AUTOSAR XML (schema 00046)
package /Cluster
  flexray cluster Chassis: baudrate=10000000, action-point-offset=2, cycle=0.005, macro-per-cycle=5000, macrotick-duration=1E-6, minislot-duration=5, network-idle-time=40, number-of-minislots=492, number-of-static-slots=50, payload-length-static=4, static-slot-duration=50
    flexray physical channel ChassisA: channel-name=CHANNEL-A
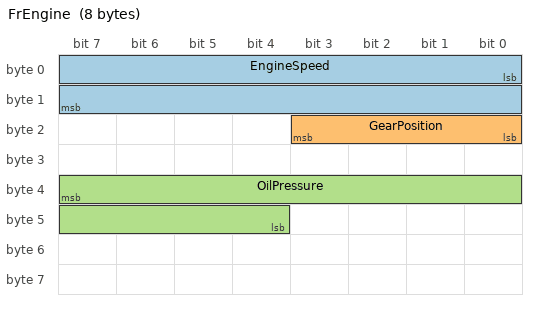
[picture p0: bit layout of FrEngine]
      frame FrEngine: frame-length=8, flexray-absolutely-scheduled-timing{communication-cycle=cycle-repetition={base-cycle=0, cycle-repetition=CYCLE-REPETITION-1}, slot-id=12}
        pdu EnginePdu: length=8, contained-i-pdu-props=header-id-short-header=0x010203
          signal EngineSpeed: start 0, 16 bit, little-endian, base-type=U16, compu {phys=raw*0.25 for raw 0..65535}, unit=rpm
          signal GearPosition: start 16, 4 bit, little-endian, base-type=U8, compu {0=Neutral, 1=First, 2=Second}
          signal OilPressure: start 39, 12 bit, big-endian, base-type=U16, compu {phys=raw*0.5-100 for raw 0..4095}, unit=kPa
      frame FrWheels: frame-length=8, flexray-absolutely-scheduled-timing{communication-cycle=cycle-repetition={base-cycle=1, cycle-repetition=CYCLE-REPETITION-4}, slot-id=40}
        pdu WheelPdu: length=8
          signal WheelSpeedFrontLeft: start 0, 16 bit, little-endian, base-type=U16, compu {phys=raw*0.01 for raw 0..65535}, unit=km/h
      frame FrCombined: frame-length=16, flexray-absolutely-scheduled-timing{communication-cycle=cycle-repetition={base-cycle=0, cycle-repetition=CYCLE-REPETITION-1}, slot-id=60}
        carries pdu EnginePdu: packing-byte-order=little-endian, start-position=0, update-indication-bit-position=120
        carries pdu WheelPdu: packing-byte-order=little-endian, start-position=64, update-indication-bit-position=121
      frame FrStatus: frame-length=8, flexray-absolutely-scheduled-timing{communication-cycle=cycle-counter=3, slot-id=50}
        pdu StatusPdu: length=2, contained-i-pdu-props=header-id-short-header=0x0A0B0C
          signal AliveCounter: start 0, 8 bit, little-endian, base-type=U8, compu {identical}
    flexray physical channel ChassisB: channel-name=CHANNEL-B
      frame FrEngine: frame-length=8, flexray-absolutely-scheduled-timing{communication-cycle=cycle-repetition={base-cycle=0, cycle-repetition=CYCLE-REPETITION-1}, slot-id=12}
        carries pdu EnginePdu: start-position=0
  flexray cluster Body
    flexray physical channel BodyA: channel-name=CHANNEL-A
      frame FrStatus: frame-length=8, flexray-absolutely-scheduled-timing{communication-cycle=cycle-repetition={base-cycle=0, cycle-repetition=CYCLE-REPETITION-2}, slot-id=5}
        carries pdu StatusPdu: start-position=0
package /Ecu
  ecu instance EngineEcu
    flexray communication controller EngineEcu_FR: key-slot-id=12, key-slot-used-for-start-up=true, key-slot-used-for-sync=true, micro-per-cycle=200000
package /ContainerIPdu
  container i pdu Bundle: length=64, contained-pdu-triggering=[EnginePdu_triggering, StatusPdu_triggering], header-type=SHORT-HEADER
package /Unit
  unit rpm: display-name=rpm
  unit kPa: display-name=kPa
  unit kmh: display-name=km/h
package /SwBaseType
  base type U8: category=FIXED_LENGTH, base-type-size=8, base-type-encoding=NONE
  base type U16: category=FIXED_LENGTH, base-type-size=16, base-type-encoding=NONE
package /System
  system TestSystem: category=SYSTEM_EXTRACT, container-i-pdu-header-byte-order=big-endian
